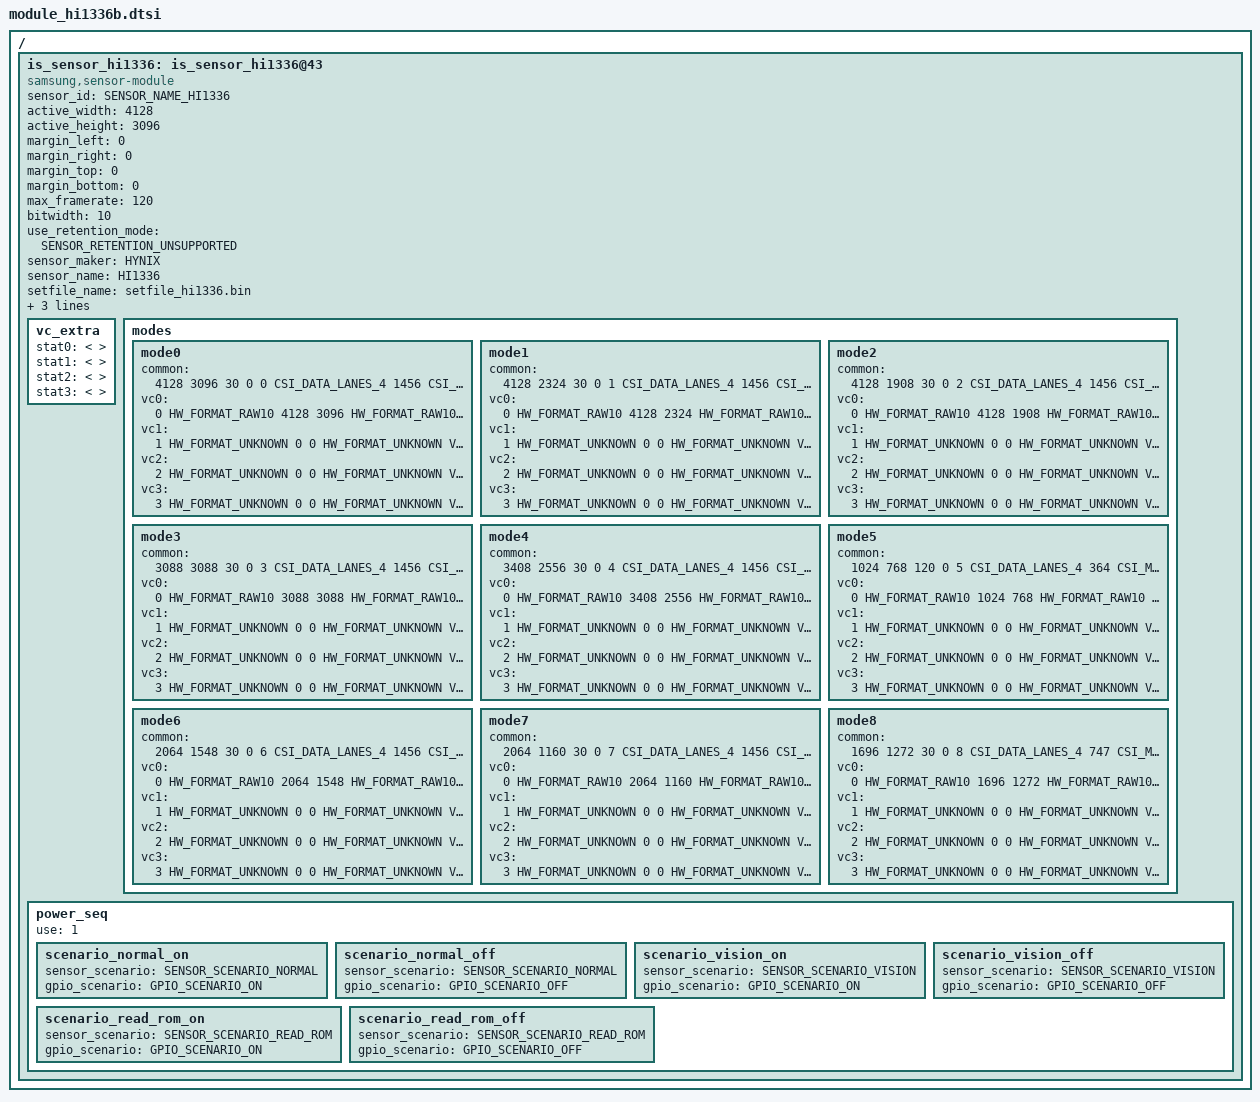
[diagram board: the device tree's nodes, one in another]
/*
 * SAMSUNG EXYNOSxxxx board camera device tree source
 *
 * Copyright (c) 2019 Samsung Electronics Co., Ltd.
 *		http://www.samsung.com
 *
 * This program is free software; you can redistribute it and/or modify
 * it under the terms of the GNU General Public License version 2 as
 * published by the Free Software Foundation.
 */

#include <dt-bindings/camera/exynos_is_dt.h>

#ifndef USE_VENDOR_PWR_PIN_NAME
#define HI1336B_IOVDD	<>
#define HI1336B_AVDD	<>
#define HI1336B_DVDD	<>
#endif

/ {
	fragment@camera {
		target-path = "/";
		__overlay__ {
			is_sensor_hi1336: is_sensor_hi1336@43 {
				compatible = "samsung,sensor-module";

				/* common */
				sensor_id = <SENSOR_NAME_HI1336>;
				active_width = <4128>;
				active_height = <3096>;
				margin_left = <0>;
				margin_right = <0>;
				margin_top = <0>;
				margin_bottom = <0>;
				max_framerate = <120>;
				bitwidth = <10>;
				use_retention_mode = <SENSOR_RETENTION_UNSUPPORTED>;
				sensor_maker = "HYNIX";
				sensor_name = "HI1336";
				setfile_name = "setfile_hi1336.bin";

				hi1336b_iovdd-supply = HI1336B_IOVDD;
				hi1336b_avdd-supply = HI1336B_AVDD;
				hi1336b_dvdd-supply = HI1336B_DVDD;
				
				status = "okay";

				vc_extra {
					/* ex) statX = <stat_type, sensor_mode, max_width, max_height, max_element> */
					stat0 = </* not avaliable */>;	/* VC_BUF_DATA_TYPE_SENSOR_STAT1 */
					stat1 = </* not avaliable */>;	/* VC_BUF_DATA_TYPE_GENERAL_STAT1 */
					stat2 = </* not avaliable */>;	/* VC_BUF_DATA_TYPE_SENSOR_STAT2 */
					stat3 = </* not avaliable */>;	/* VC_BUF_DATA_TYPE_GENERAL_STAT2 */
				};

				/*
				* Reference File : Hi-1336_setting_v4.0.3_SEC25_20220905.xlsx
				*
				*  [ 0 ] 4128 x 3096(4:3)      @30,  MIPI lane: 4, MIPI data rate(Mbps/lane):  1456, Mclk(Mhz): 26
				*  [ 1 ] 4128 x 2324(16:9)     @30,  MIPI lane: 4, MIPI data rate(Mbps/lane):  1456, Mclk(Mhz): 26
				*  [ 2 ] 3088 x 3088(1:1)      @30,  MIPI lane: 4, MIPI data rate(Mbps/lane):  1456, Mclk(Mhz): 26
				*/

				/* sensor modes */
				modes {
						/* common = <width, height, fps, settle, mode, lane, speed, interleave, lrte, pd_mode> */
						/* vcX = <map, hwformat, width, height, hwformat, type, width, height> */

					mode0 {
						common = <4128 3096 30 0 0 CSI_DATA_LANES_4 1456 CSI_MODE_CH0_ONLY LRTE_DISABLE PD_NONE EX_NONE>;
						vc0 = <0 HW_FORMAT_RAW10 4128 3096	/* out */ HW_FORMAT_RAW10 VC_NOTHING 0 0>;
						vc1 = <1 HW_FORMAT_UNKNOWN 0 0		/* out */ HW_FORMAT_UNKNOWN VC_NOTHING 0 0>;
						vc2 = <2 HW_FORMAT_UNKNOWN 0 0		/* out */ HW_FORMAT_UNKNOWN VC_NOTHING 0 0>;
						vc3 = <3 HW_FORMAT_UNKNOWN 0 0		/* out */ HW_FORMAT_UNKNOWN VC_NOTHING 0 0>;
					};
					mode1 {
						common = <4128 2324 30 0 1 CSI_DATA_LANES_4 1456 CSI_MODE_CH0_ONLY LRTE_DISABLE PD_NONE EX_NONE>;
						vc0 = <0 HW_FORMAT_RAW10 4128 2324	/* out */ HW_FORMAT_RAW10 VC_NOTHING 0 0>;
						vc1 = <1 HW_FORMAT_UNKNOWN 0 0		/* out */ HW_FORMAT_UNKNOWN VC_NOTHING 0 0>;
						vc2 = <2 HW_FORMAT_UNKNOWN 0 0		/* out */ HW_FORMAT_UNKNOWN VC_NOTHING 0 0>;
						vc3 = <3 HW_FORMAT_UNKNOWN 0 0		/* out */ HW_FORMAT_UNKNOWN VC_NOTHING 0 0>;
					};
					mode2 {
						common = <4128 1908 30 0 2 CSI_DATA_LANES_4 1456 CSI_MODE_CH0_ONLY LRTE_DISABLE PD_NONE EX_NONE>;
						vc0 = <0 HW_FORMAT_RAW10 4128 1908	/* out */ HW_FORMAT_RAW10 VC_NOTHING 0 0>;
						vc1 = <1 HW_FORMAT_UNKNOWN 0 0		/* out */ HW_FORMAT_UNKNOWN VC_NOTHING 0 0>;
						vc2 = <2 HW_FORMAT_UNKNOWN 0 0		/* out */ HW_FORMAT_UNKNOWN VC_NOTHING 0 0>;
						vc3 = <3 HW_FORMAT_UNKNOWN 0 0		/* out */ HW_FORMAT_UNKNOWN VC_NOTHING 0 0>;
					};
					mode3 {
						common = <3088 3088 30 0 3 CSI_DATA_LANES_4 1456 CSI_MODE_CH0_ONLY LRTE_DISABLE PD_NONE EX_NONE>;
						vc0 = <0 HW_FORMAT_RAW10 3088 3088	/* out */ HW_FORMAT_RAW10 VC_NOTHING 0 0>;
						vc1 = <1 HW_FORMAT_UNKNOWN 0 0		/* out */ HW_FORMAT_UNKNOWN VC_NOTHING 0 0>;
						vc2 = <2 HW_FORMAT_UNKNOWN 0 0		/* out */ HW_FORMAT_UNKNOWN VC_NOTHING 0 0>;
						vc3 = <3 HW_FORMAT_UNKNOWN 0 0		/* out */ HW_FORMAT_UNKNOWN VC_NOTHING 0 0>;
					};
					mode4 {
						common = <3408 2556 30 0 4 CSI_DATA_LANES_4 1456 CSI_MODE_CH0_ONLY LRTE_DISABLE PD_NONE EX_NONE>;
						vc0 = <0 HW_FORMAT_RAW10 3408 2556	/* out */ HW_FORMAT_RAW10 VC_NOTHING 0 0>;
						vc1 = <1 HW_FORMAT_UNKNOWN 0 0		/* out */ HW_FORMAT_UNKNOWN VC_NOTHING 0 0>;
						vc2 = <2 HW_FORMAT_UNKNOWN 0 0		/* out */ HW_FORMAT_UNKNOWN VC_NOTHING 0 0>;
						vc3 = <3 HW_FORMAT_UNKNOWN 0 0		/* out */ HW_FORMAT_UNKNOWN VC_NOTHING 0 0>;
					};
					mode5 {
						common = <1024 768 120 0 5 CSI_DATA_LANES_4 364 CSI_MODE_CH0_ONLY LRTE_DISABLE PD_NONE EX_NONE>;
						vc0 = <0 HW_FORMAT_RAW10 1024 768	/* out */ HW_FORMAT_RAW10 VC_NOTHING 0 0>;
						vc1 = <1 HW_FORMAT_UNKNOWN 0 0		/* out */ HW_FORMAT_UNKNOWN VC_NOTHING 0 0>;
						vc2 = <2 HW_FORMAT_UNKNOWN 0 0		/* out */ HW_FORMAT_UNKNOWN VC_NOTHING 0 0>;
						vc3 = <3 HW_FORMAT_UNKNOWN 0 0		/* out */ HW_FORMAT_UNKNOWN VC_NOTHING 0 0>;
					};
					mode6 {
						common = <2064 1548 30 0 6 CSI_DATA_LANES_4 1456 CSI_MODE_CH0_ONLY LRTE_DISABLE PD_NONE EX_NONE>;
						vc0 = <0 HW_FORMAT_RAW10 2064 1548	/* out */ HW_FORMAT_RAW10 VC_NOTHING 0 0>;
						vc1 = <1 HW_FORMAT_UNKNOWN 0 0		/* out */ HW_FORMAT_UNKNOWN VC_NOTHING 0 0>;
						vc2 = <2 HW_FORMAT_UNKNOWN 0 0		/* out */ HW_FORMAT_UNKNOWN VC_NOTHING 0 0>;
						vc3 = <3 HW_FORMAT_UNKNOWN 0 0		/* out */ HW_FORMAT_UNKNOWN VC_NOTHING 0 0>;
					};
					mode7 {
						common = <2064 1160 30 0 7 CSI_DATA_LANES_4 1456 CSI_MODE_CH0_ONLY LRTE_DISABLE PD_NONE EX_NONE>;
						vc0 = <0 HW_FORMAT_RAW10 2064 1160	/* out */ HW_FORMAT_RAW10 VC_NOTHING 0 0>;
						vc1 = <1 HW_FORMAT_UNKNOWN 0 0		/* out */ HW_FORMAT_UNKNOWN VC_NOTHING 0 0>;
						vc2 = <2 HW_FORMAT_UNKNOWN 0 0		/* out */ HW_FORMAT_UNKNOWN VC_NOTHING 0 0>;
						vc3 = <3 HW_FORMAT_UNKNOWN 0 0		/* out */ HW_FORMAT_UNKNOWN VC_NOTHING 0 0>;
					};
					mode8 {
						common = <1696 1272 30 0 8 CSI_DATA_LANES_4 747 CSI_MODE_CH0_ONLY LRTE_DISABLE PD_NONE EX_NONE>;
						vc0 = <0 HW_FORMAT_RAW10 1696 1272	/* out */ HW_FORMAT_RAW10 VC_NOTHING 0 0>;
						vc1 = <1 HW_FORMAT_UNKNOWN 0 0		/* out */ HW_FORMAT_UNKNOWN VC_NOTHING 0 0>;
						vc2 = <2 HW_FORMAT_UNKNOWN 0 0		/* out */ HW_FORMAT_UNKNOWN VC_NOTHING 0 0>;
						vc3 = <3 HW_FORMAT_UNKNOWN 0 0		/* out */ HW_FORMAT_UNKNOWN VC_NOTHING 0 0>;
					};
				};

				power_seq {
					use = <1>;
					scenario_normal_on {
						sensor_scenario = <SENSOR_SCENARIO_NORMAL>;
						gpio_scenario = <GPIO_SCENARIO_ON>;

						/* A start node number should be over the 10 for reserved number 0~9. */
						/* pname = "name"; pin = <act value dealy voltage>; gpio = <gpx# # 0x1>; */
					};

					scenario_normal_off {
						sensor_scenario = <SENSOR_SCENARIO_NORMAL>;
						gpio_scenario = <GPIO_SCENARIO_OFF>;

						/* A start node number should be over the 10 for reserved number 0~9. */
						/* pname = "name"; pin = <act value dealy voltage>; gpio = <gpx# # 0x1>; */
					};

					scenario_vision_on {
						sensor_scenario = <SENSOR_SCENARIO_VISION>;
						gpio_scenario = <GPIO_SCENARIO_ON>;

						/* A start node number should be over the 10 for reserved number 0~9. */
						/* pname = "name"; pin = <act value dealy voltage>; gpio = <gpx# # 0x1>; */
					};

					scenario_vision_off {
						sensor_scenario = <SENSOR_SCENARIO_VISION>;
						gpio_scenario = <GPIO_SCENARIO_OFF>;

						/* A start node number should be over the 10 for reserved number 0~9. */
						/* pname = "name"; pin = <act value dealy voltage>; gpio = <gpx# # 0x1>; */
					};

					scenario_read_rom_on {
						sensor_scenario = <SENSOR_SCENARIO_READ_ROM>;
						gpio_scenario = <GPIO_SCENARIO_ON>;
					};

					scenario_read_rom_off {
						sensor_scenario = <SENSOR_SCENARIO_READ_ROM>;
						gpio_scenario = <GPIO_SCENARIO_OFF>;
					};
				};
			};
		}; /* end of __overlay__ */
	}; /* end of fragment */
}; /* end of root */
